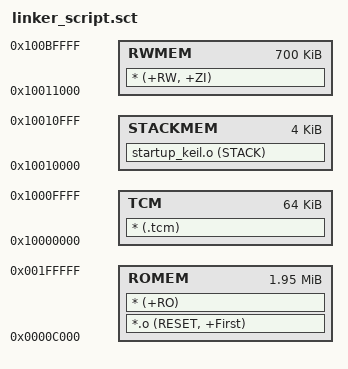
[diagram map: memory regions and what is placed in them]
;******************************************************************************
;
; Scatter file for Keil linker configuration.
;
;******************************************************************************
LR_1 0x0000C000
{
    ROMEM 0x0000C000 0x001F4000
    {
        *.o (RESET, +First)
        * (+RO)
    }

    RWMEM 0x10011000 0x000AF000
    {
        * (+RW, +ZI)
    }

    TCM 0x10000000 0x00010000
    {
        * (.tcm)
    }

    STACKMEM 0x10010000 0x00001000
    {
        startup_keil.o (STACK)
    }
}
